VERSION "Toyota/Continental ARS510 radar bus (comma harness bus 1), frame-level. Object records need reassembly: see ars510/ and dbc/ars510_objects_vbus.dbc"

NS_ :

BS_:

BU_: RADAR CAMERA XXX

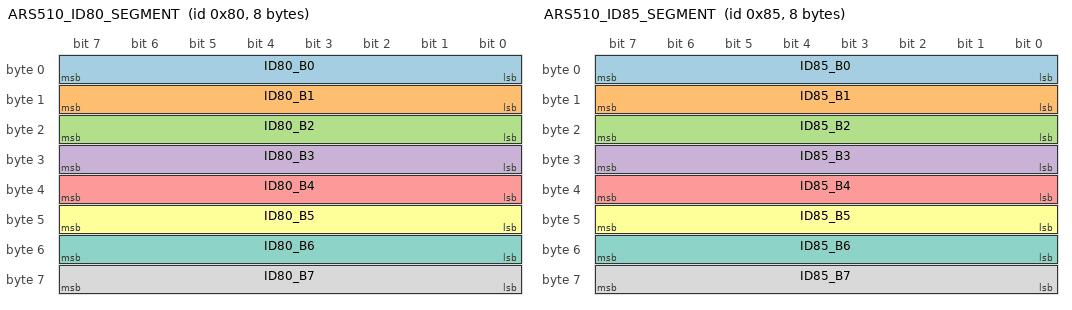
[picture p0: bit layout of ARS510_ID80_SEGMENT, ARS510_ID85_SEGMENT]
BO_ 128 ARS510_ID80_SEGMENT: 8 RADAR
 SG_ ID80_B0 : 0|8@1+ (1,0) [0|255] "raw" RADAR
 SG_ ID80_B1 : 8|8@1+ (1,0) [0|255] "raw" RADAR
 SG_ ID80_B2 : 16|8@1+ (1,0) [0|255] "raw" RADAR
 SG_ ID80_B3 : 24|8@1+ (1,0) [0|255] "raw" RADAR
 SG_ ID80_B4 : 32|8@1+ (1,0) [0|255] "raw" RADAR
 SG_ ID80_B5 : 40|8@1+ (1,0) [0|255] "raw" RADAR
 SG_ ID80_B6 : 48|8@1+ (1,0) [0|255] "raw" RADAR
 SG_ ID80_B7 : 56|8@1+ (1,0) [0|255] "raw" RADAR

BO_ 133 ARS510_ID85_SEGMENT: 8 RADAR
 SG_ ID85_B0 : 0|8@1+ (1,0) [0|255] "raw" RADAR
 SG_ ID85_B1 : 8|8@1+ (1,0) [0|255] "raw" RADAR
 SG_ ID85_B2 : 16|8@1+ (1,0) [0|255] "raw" RADAR
 SG_ ID85_B3 : 24|8@1+ (1,0) [0|255] "raw" RADAR
 SG_ ID85_B4 : 32|8@1+ (1,0) [0|255] "raw" RADAR
 SG_ ID85_B5 : 40|8@1+ (1,0) [0|255] "raw" RADAR
 SG_ ID85_B6 : 48|8@1+ (1,0) [0|255] "raw" RADAR
 SG_ ID85_B7 : 56|8@1+ (1,0) [0|255] "raw" RADAR

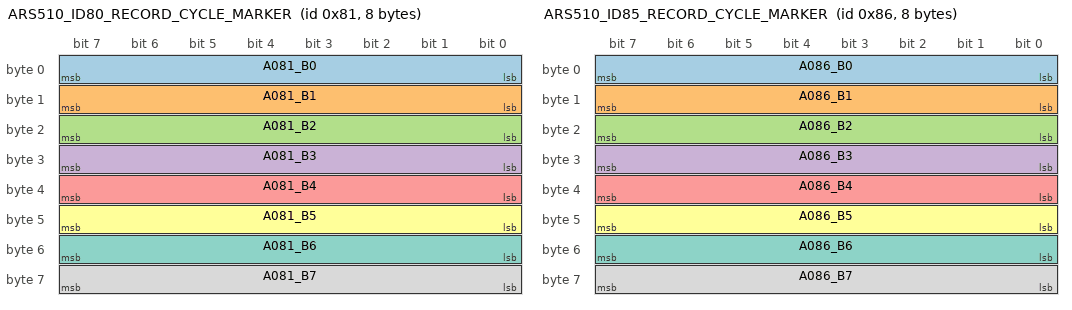
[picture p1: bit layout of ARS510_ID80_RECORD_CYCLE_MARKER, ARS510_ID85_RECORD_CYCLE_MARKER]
BO_ 129 ARS510_ID80_RECORD_CYCLE_MARKER: 8 RADAR
 SG_ A081_B0 : 0|8@1+ (1,0) [0|255] "raw" RADAR
 SG_ A081_B1 : 8|8@1+ (1,0) [0|255] "raw" RADAR
 SG_ A081_B2 : 16|8@1+ (1,0) [0|255] "raw" RADAR
 SG_ A081_B3 : 24|8@1+ (1,0) [0|255] "raw" RADAR
 SG_ A081_B4 : 32|8@1+ (1,0) [0|255] "raw" RADAR
 SG_ A081_B5 : 40|8@1+ (1,0) [0|255] "raw" RADAR
 SG_ A081_B6 : 48|8@1+ (1,0) [0|255] "raw" RADAR
 SG_ A081_B7 : 56|8@1+ (1,0) [0|255] "raw" RADAR

BO_ 134 ARS510_ID85_RECORD_CYCLE_MARKER: 8 RADAR
 SG_ A086_B0 : 0|8@1+ (1,0) [0|255] "raw" RADAR
 SG_ A086_B1 : 8|8@1+ (1,0) [0|255] "raw" RADAR
 SG_ A086_B2 : 16|8@1+ (1,0) [0|255] "raw" RADAR
 SG_ A086_B3 : 24|8@1+ (1,0) [0|255] "raw" RADAR
 SG_ A086_B4 : 32|8@1+ (1,0) [0|255] "raw" RADAR
 SG_ A086_B5 : 40|8@1+ (1,0) [0|255] "raw" RADAR
 SG_ A086_B6 : 48|8@1+ (1,0) [0|255] "raw" RADAR
 SG_ A086_B7 : 56|8@1+ (1,0) [0|255] "raw" RADAR

BO_ 256 ARS510_A100_CANDIDATE: 7 RADAR
 SG_ A100_STARTUP_WORD_BE16 : 7|16@0+ (1,0) [0|65535] "raw" RADAR
 SG_ A100_B2_B6_RESERVED_ZERO40 : 23|40@0+ (1,0) [0|1099511627775] "raw" RADAR

BO_ 257 ARS510_A101_CANDIDATE: 6 CAMERA
 SG_ A101_STARTUP_STATE8 : 0|8@1+ (1,0) [0|255] "state" RADAR
 SG_ A101_B1_B5_RESERVED_ZERO40 : 15|40@0+ (1,0) [0|1099511627775] "raw" RADAR

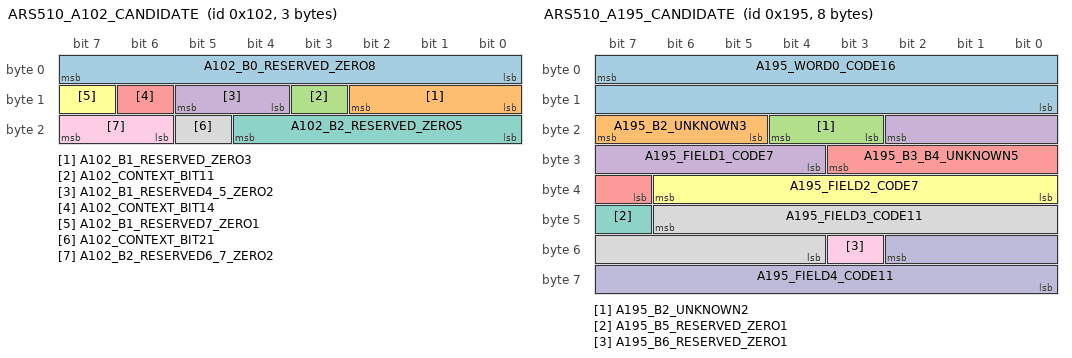
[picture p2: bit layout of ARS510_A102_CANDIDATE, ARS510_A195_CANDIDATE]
BO_ 258 ARS510_A102_CANDIDATE: 3 CAMERA
 SG_ A102_B0_RESERVED_ZERO8 : 0|8@1+ (1,0) [0|255] "raw" RADAR
 SG_ A102_B1_RESERVED_ZERO3 : 8|3@1+ (1,0) [0|7] "raw" RADAR
 SG_ A102_CONTEXT_BIT11 : 11|1@1+ (1,0) [0|1] "state" RADAR
 SG_ A102_B1_RESERVED4_5_ZERO2 : 12|2@1+ (1,0) [0|3] "raw" RADAR
 SG_ A102_CONTEXT_BIT14 : 14|1@1+ (1,0) [0|1] "state" RADAR
 SG_ A102_B1_RESERVED7_ZERO1 : 15|1@1+ (1,0) [0|1] "raw" RADAR
 SG_ A102_B2_RESERVED_ZERO5 : 16|5@1+ (1,0) [0|31] "raw" RADAR
 SG_ A102_CONTEXT_BIT21 : 21|1@1+ (1,0) [0|1] "state" RADAR
 SG_ A102_B2_RESERVED6_7_ZERO2 : 22|2@1+ (1,0) [0|3] "raw" RADAR

BO_ 259 ARS510_A103_CANDIDATE: 2 RADAR
 SG_ A103_B0_RESERVED_ZERO8 : 0|8@1+ (1,0) [0|255] "raw" RADAR
 SG_ A103_B1_RESERVED_ZERO8 : 8|8@1+ (1,0) [0|255] "raw" RADAR

BO_ 384 ARS510_A180_CANDIDATE: 5 CAMERA
 SG_ A180_OBSERVED_CONSTANT_BE40 : 7|40@0+ (1,0) [0|1099511627775] "raw" RADAR

BO_ 400 ARS510_A190_CANDIDATE: 7 RADAR
 SG_ A190_STATUS_0_4 : 0|4@1+ (1,0) [0|15] "state" RADAR
 SG_ A190_B0_HIGH4 : 4|4@1+ (1,0) [0|15] "raw" RADAR
 SG_ A190_ACTIVE_SUMMARIES : 3|2@0+ (1,0) [0|3] "count" RADAR
 SG_ A190_B1 : 8|8@1+ (1,0) [0|255] "raw" RADAR
 SG_ A190_TIMESTAMP_US : 23|32@0+ (1,0) [0|4294967295] "us" RADAR
 SG_ A190_COUNTER_RESERVED0 : 48|4@1+ (1,0) [0|15] "raw" RADAR
 SG_ A190_COUNTER4 : 52|4@1+ (1,0) [0|15] "counter" RADAR

BO_ 405 ARS510_A195_CANDIDATE: 8 RADAR
 SG_ A195_WORD0_CODE16 : 7|16@0+ (1,0) [0|65535] "code" RADAR
 SG_ A195_B2_UNKNOWN3 : 23|3@0+ (1,0) [0|7] "raw" RADAR
 SG_ A195_B2_UNKNOWN2 : 20|2@0+ (1,0) [0|3] "raw" RADAR
 SG_ A195_FIELD1_CODE7 : 18|7@0+ (1,0) [0|127] "code" RADAR
 SG_ A195_B3_B4_UNKNOWN5 : 27|5@0+ (1,0) [0|31] "raw" RADAR
 SG_ A195_FIELD2_CODE7 : 38|7@0+ (1,0) [0|127] "code" RADAR
 SG_ A195_B5_RESERVED_ZERO1 : 47|1@0+ (1,0) [0|1] "raw" RADAR
 SG_ A195_FIELD3_CODE11 : 46|11@0+ (1,0) [0|2047] "code" RADAR
 SG_ A195_B6_RESERVED_ZERO1 : 51|1@0+ (1,0) [0|1] "raw" RADAR
 SG_ A195_FIELD4_CODE11 : 50|11@0+ (1,0) [0|2047] "code" RADAR

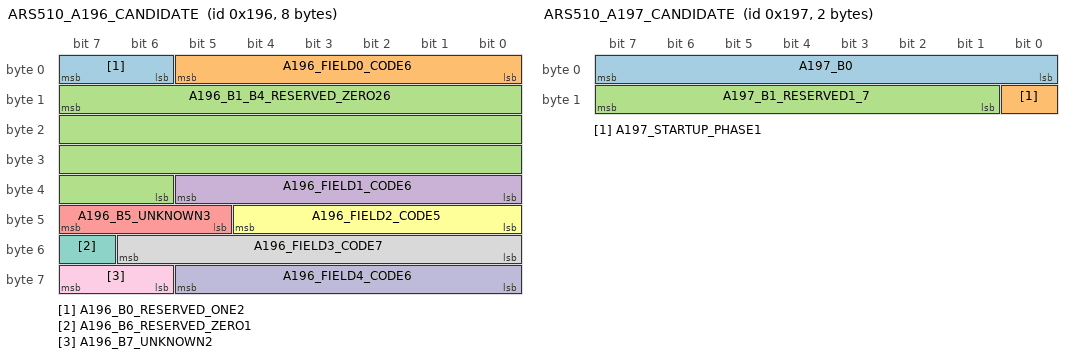
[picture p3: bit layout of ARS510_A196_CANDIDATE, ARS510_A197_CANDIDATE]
BO_ 406 ARS510_A196_CANDIDATE: 8 RADAR
 SG_ A196_B0_RESERVED_ONE2 : 7|2@0+ (1,0) [0|3] "raw" RADAR
 SG_ A196_FIELD0_CODE6 : 5|6@0+ (1,0) [0|63] "code" RADAR
 SG_ A196_B1_B4_RESERVED_ZERO26 : 15|26@0+ (1,0) [0|67108863] "raw" RADAR
 SG_ A196_FIELD1_CODE6 : 37|6@0+ (1,0) [0|63] "code" RADAR
 SG_ A196_B5_UNKNOWN3 : 47|3@0+ (1,0) [0|7] "raw" RADAR
 SG_ A196_FIELD2_CODE5 : 44|5@0+ (1,0) [0|31] "code" RADAR
 SG_ A196_B6_RESERVED_ZERO1 : 55|1@0+ (1,0) [0|1] "raw" RADAR
 SG_ A196_FIELD3_CODE7 : 54|7@0+ (1,0) [0|127] "code" RADAR
 SG_ A196_B7_UNKNOWN2 : 63|2@0+ (1,0) [0|3] "raw" RADAR
 SG_ A196_FIELD4_CODE6 : 61|6@0+ (1,0) [0|63] "code" RADAR

BO_ 407 ARS510_A197_CANDIDATE: 2 CAMERA
 SG_ A197_B0 : 0|8@1+ (1,0) [0|255] "raw" RADAR
 SG_ A197_STARTUP_PHASE1 : 8|1@1+ (1,0) [0|1] "state" RADAR
 SG_ A197_B1_RESERVED1_7 : 9|7@1+ (1,0) [0|127] "raw" RADAR

BO_ 408 ARS510_A198_CANDIDATE: 1 RADAR
 SG_ A198_OBSERVED_CONSTANT_BE8 : 7|8@0+ (1,0) [0|255] "raw" RADAR

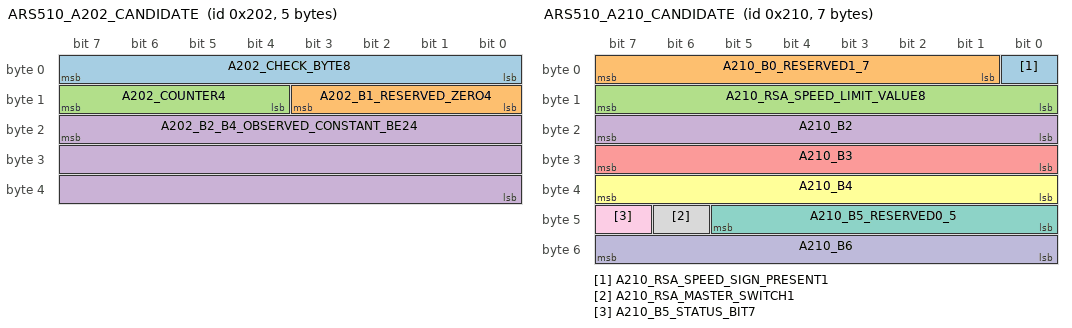
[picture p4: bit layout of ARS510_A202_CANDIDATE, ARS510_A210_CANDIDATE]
BO_ 514 ARS510_A202_CANDIDATE: 5 RADAR
 SG_ A202_CHECK_BYTE8 : 0|8@1+ (1,0) [0|255] "debug" RADAR
 SG_ A202_B1_RESERVED_ZERO4 : 8|4@1+ (1,0) [0|15] "raw" RADAR
 SG_ A202_COUNTER4 : 12|4@1+ (1,0) [0|15] "counter" RADAR
 SG_ A202_B2_B4_OBSERVED_CONSTANT_BE24 : 23|24@0+ (1,0) [0|16777215] "raw" RADAR

BO_ 528 ARS510_A210_CANDIDATE: 7 CAMERA
 SG_ A210_RSA_SPEED_SIGN_PRESENT1 : 0|1@1+ (1,0) [0|1] "state" RADAR
 SG_ A210_B0_RESERVED1_7 : 1|7@1+ (1,0) [0|127] "raw" RADAR
 SG_ A210_RSA_SPEED_LIMIT_VALUE8 : 8|8@1+ (1,0) [0|255] "display_speed" RADAR
 SG_ A210_B2 : 16|8@1+ (1,0) [0|255] "raw" RADAR
 SG_ A210_B3 : 24|8@1+ (1,0) [0|255] "raw" RADAR
 SG_ A210_B4 : 32|8@1+ (1,0) [0|255] "raw" RADAR
 SG_ A210_B5_RESERVED0_5 : 40|6@1+ (1,0) [0|63] "raw" RADAR
 SG_ A210_RSA_MASTER_SWITCH1 : 46|1@1+ (1,0) [0|1] "state" RADAR
 SG_ A210_B5_STATUS_BIT7 : 47|1@1+ (1,0) [0|1] "state" RADAR
 SG_ A210_B6 : 48|8@1+ (1,0) [0|255] "raw" RADAR

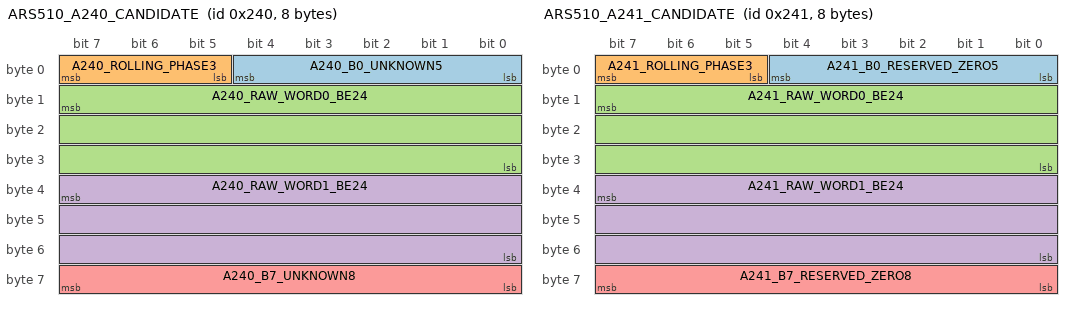
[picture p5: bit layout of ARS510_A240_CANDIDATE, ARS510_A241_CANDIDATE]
BO_ 576 ARS510_A240_CANDIDATE: 8 CAMERA
 SG_ A240_B0_UNKNOWN5 : 0|5@1+ (1,0) [0|31] "raw" RADAR
 SG_ A240_ROLLING_PHASE3 : 5|3@1+ (1,0) [0|7] "state" RADAR
 SG_ A240_RAW_WORD0_BE24 : 15|24@0+ (1,0) [0|16777215] "raw" RADAR
 SG_ A240_RAW_WORD1_BE24 : 39|24@0+ (1,0) [0|16777215] "raw" RADAR
 SG_ A240_B7_UNKNOWN8 : 56|8@1+ (1,0) [0|255] "raw" RADAR

BO_ 577 ARS510_A241_CANDIDATE: 8 CAMERA
 SG_ A241_B0_RESERVED_ZERO5 : 0|5@1+ (1,0) [0|31] "raw" RADAR
 SG_ A241_ROLLING_PHASE3 : 5|3@1+ (1,0) [0|7] "state" RADAR
 SG_ A241_RAW_WORD0_BE24 : 15|24@0+ (1,0) [0|16777215] "raw" RADAR
 SG_ A241_RAW_WORD1_BE24 : 39|24@0+ (1,0) [0|16777215] "raw" RADAR
 SG_ A241_B7_RESERVED_ZERO8 : 56|8@1+ (1,0) [0|255] "raw" RADAR

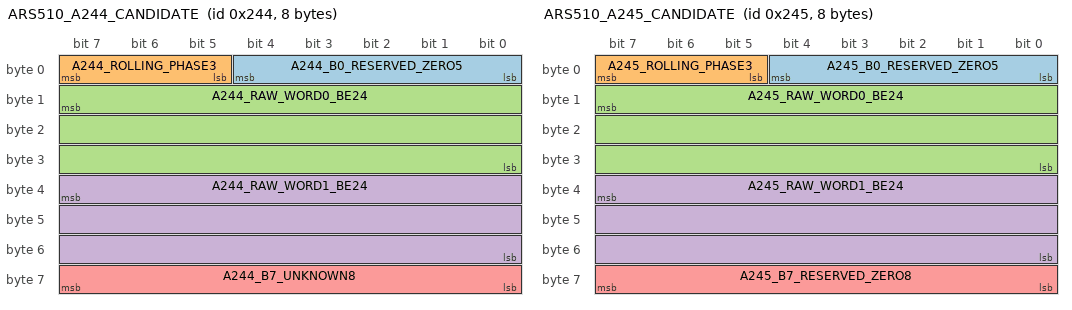
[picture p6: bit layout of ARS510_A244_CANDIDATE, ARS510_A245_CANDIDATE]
BO_ 580 ARS510_A244_CANDIDATE: 8 CAMERA
 SG_ A244_B0_RESERVED_ZERO5 : 0|5@1+ (1,0) [0|31] "raw" RADAR
 SG_ A244_ROLLING_PHASE3 : 5|3@1+ (1,0) [0|7] "state" RADAR
 SG_ A244_RAW_WORD0_BE24 : 15|24@0+ (1,0) [0|16777215] "raw" RADAR
 SG_ A244_RAW_WORD1_BE24 : 39|24@0+ (1,0) [0|16777215] "raw" RADAR
 SG_ A244_B7_UNKNOWN8 : 56|8@1+ (1,0) [0|255] "raw" RADAR

BO_ 581 ARS510_A245_CANDIDATE: 8 CAMERA
 SG_ A245_B0_RESERVED_ZERO5 : 0|5@1+ (1,0) [0|31] "raw" RADAR
 SG_ A245_ROLLING_PHASE3 : 5|3@1+ (1,0) [0|7] "state" RADAR
 SG_ A245_RAW_WORD0_BE24 : 15|24@0+ (1,0) [0|16777215] "raw" RADAR
 SG_ A245_RAW_WORD1_BE24 : 39|24@0+ (1,0) [0|16777215] "raw" RADAR
 SG_ A245_B7_RESERVED_ZERO8 : 56|8@1+ (1,0) [0|255] "raw" RADAR

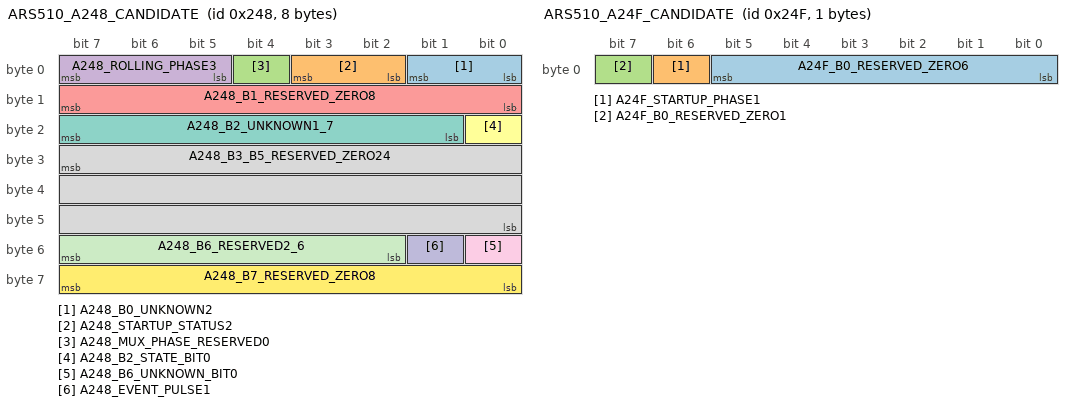
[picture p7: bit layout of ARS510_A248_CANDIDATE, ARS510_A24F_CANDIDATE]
BO_ 584 ARS510_A248_CANDIDATE: 8 CAMERA
 SG_ A248_B0_UNKNOWN2 : 0|2@1+ (1,0) [0|3] "raw" RADAR
 SG_ A248_STARTUP_STATUS2 : 2|2@1+ (1,0) [0|3] "state" RADAR
 SG_ A248_MUX_PHASE_RESERVED0 : 4|1@1+ (1,0) [0|1] "raw" RADAR
 SG_ A248_ROLLING_PHASE3 : 5|3@1+ (1,0) [0|7] "state" RADAR
 SG_ A248_B1_RESERVED_ZERO8 : 8|8@1+ (1,0) [0|255] "raw" RADAR
 SG_ A248_B2_STATE_BIT0 : 16|1@1+ (1,0) [0|1] "state" RADAR
 SG_ A248_B2_UNKNOWN1_7 : 17|7@1+ (1,0) [0|127] "raw" RADAR
 SG_ A248_B3_B5_RESERVED_ZERO24 : 31|24@0+ (1,0) [0|16777215] "raw" RADAR
 SG_ A248_B6_UNKNOWN_BIT0 : 48|1@1+ (1,0) [0|1] "raw" RADAR
 SG_ A248_EVENT_PULSE1 : 49|1@1+ (1,0) [0|1] "state" RADAR
 SG_ A248_B6_RESERVED2_6 : 50|6@1+ (1,0) [0|63] "raw" RADAR
 SG_ A248_B7_RESERVED_ZERO8 : 56|8@1+ (1,0) [0|255] "raw" RADAR

BO_ 589 ARS510_A24D_CANDIDATE: 7 CAMERA
 SG_ A24D_OBSERVED_CONSTANT_BE56 : 7|56@0+ (1,0) [0|72057594037927935] "raw" RADAR

BO_ 591 ARS510_A24F_CANDIDATE: 1 RADAR
 SG_ A24F_B0_RESERVED_ZERO6 : 0|6@1+ (1,0) [0|63] "raw" RADAR
 SG_ A24F_STARTUP_PHASE1 : 6|1@1+ (1,0) [0|1] "state" RADAR
 SG_ A24F_B0_RESERVED_ZERO1 : 7|1@1+ (1,0) [0|1] "raw" RADAR

BO_ 1280 ARS510_A500_CANDIDATE: 6 CAMERA
 SG_ A500_OBSERVED_CONSTANT_BE48 : 7|48@0+ (1,0) [0|281474976710655] "raw" RADAR

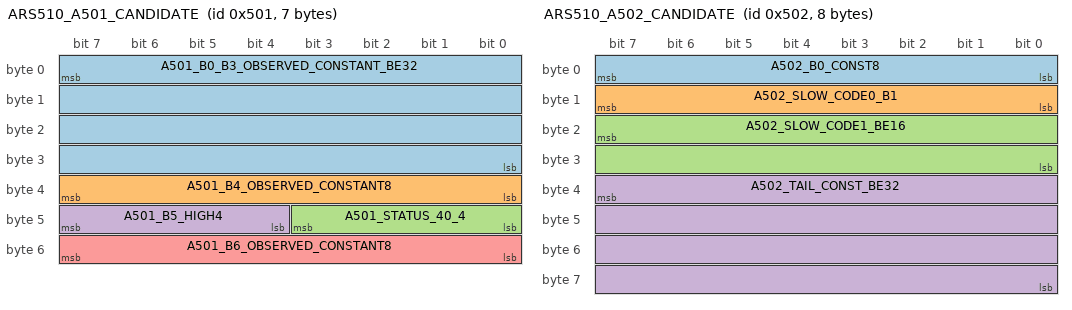
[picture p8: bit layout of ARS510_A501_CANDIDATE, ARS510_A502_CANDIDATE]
BO_ 1281 ARS510_A501_CANDIDATE: 7 CAMERA
 SG_ A501_B0_B3_OBSERVED_CONSTANT_BE32 : 7|32@0+ (1,0) [0|4294967295] "raw" RADAR
 SG_ A501_B4_OBSERVED_CONSTANT8 : 32|8@1+ (1,0) [0|255] "raw" RADAR
 SG_ A501_STATUS_40_4 : 40|4@1+ (1,0) [0|15] "state" RADAR
 SG_ A501_B5_HIGH4 : 44|4@1+ (1,0) [0|15] "raw" RADAR
 SG_ A501_B6_OBSERVED_CONSTANT8 : 48|8@1+ (1,0) [0|255] "raw" RADAR

BO_ 1282 ARS510_A502_CANDIDATE: 8 RADAR
 SG_ A502_B0_CONST8 : 0|8@1+ (1,0) [0|255] "raw" RADAR
 SG_ A502_SLOW_CODE0_B1 : 8|8@1+ (1,0) [0|255] "raw" RADAR
 SG_ A502_SLOW_CODE1_BE16 : 23|16@0+ (1,0) [0|65535] "raw" RADAR
 SG_ A502_TAIL_CONST_BE32 : 39|32@0+ (1,0) [0|4294967295] "raw" RADAR

BO_ 1664 ARS510_A680_OBJECT: 8 RADAR
 SG_ A680_SELECTOR : 7|8@0+ (1,0) [0|255] "code" RADAR
 SG_ A680_LONG_DIST : 15|13@0+ (0.03125,0) [0|255.97] "m" RADAR
 SG_ A680_LAT_DIST : 18|11@0- (0.015,0) [-15.36|15.345] "m" RADAR
 SG_ A680_SPEED_OVER_GROUND : 39|10@0+ (0.15,-76.8) [-76.8|76.65] "m/s" RADAR
 SG_ A680_FLAGS : 45|6@0+ (1,0) [0|63] "raw" RADAR
 SG_ A680_STATIONARY : 40|1@0+ (1,0) [0|1] "" RADAR
 SG_ A680_ONCOMING : 41|1@0+ (1,0) [0|1] "" RADAR
 SG_ A680_SEEN_MOVING : 43|1@0+ (1,0) [0|1] "" RADAR
 SG_ A680_LAT_SPEED_CODE : 55|8@0+ (1,-128) [-128|127] "code" RADAR
 SG_ A680_B7_HIGH4 : 63|4@0+ (1,0) [0|15] "raw" RADAR
 SG_ A680_B7_LOW4 : 59|4@0+ (1,0) [0|15] "raw" RADAR

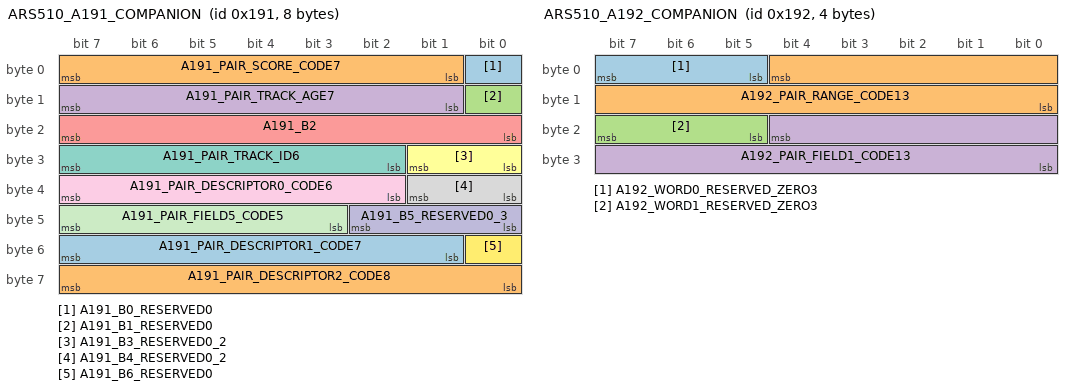
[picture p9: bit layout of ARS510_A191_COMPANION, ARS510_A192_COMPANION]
BO_ 401 ARS510_A191_COMPANION: 8 RADAR
 SG_ A191_B0_RESERVED0 : 0|1@1+ (1,0) [0|1] "raw" RADAR
 SG_ A191_PAIR_SCORE_CODE7 : 1|7@1+ (1,0) [0|127] "code" RADAR
 SG_ A191_B1_RESERVED0 : 8|1@1+ (1,0) [0|1] "raw" RADAR
 SG_ A191_PAIR_TRACK_AGE7 : 9|7@1+ (1,0) [0|127] "radar_cycle" RADAR
 SG_ A191_B2 : 16|8@1+ (1,0) [0|255] "raw" RADAR
 SG_ A191_B3_RESERVED0_2 : 24|2@1+ (1,0) [0|3] "raw" RADAR
 SG_ A191_PAIR_TRACK_ID6 : 26|6@1+ (1,0) [0|63] "code" RADAR
 SG_ A191_B4_RESERVED0_2 : 32|2@1+ (1,0) [0|3] "raw" RADAR
 SG_ A191_PAIR_DESCRIPTOR0_CODE6 : 34|6@1+ (0.1,0) [0|6.3] "m" RADAR
 SG_ A191_B5_RESERVED0_3 : 40|3@1+ (1,0) [0|7] "raw" RADAR
 SG_ A191_PAIR_FIELD5_CODE5 : 43|5@1+ (1,0) [0|31] "code" RADAR
 SG_ A191_B6_RESERVED0 : 48|1@1+ (1,0) [0|1] "raw" RADAR
 SG_ A191_PAIR_DESCRIPTOR1_CODE7 : 49|7@1+ (0.1,0) [0|12.7] "m" RADAR
 SG_ A191_PAIR_DESCRIPTOR2_CODE8 : 56|8@1+ (0.1,0) [0|25.5] "m" RADAR

BO_ 402 ARS510_A192_COMPANION: 4 RADAR
 SG_ A192_WORD0_RESERVED_ZERO3 : 5|3@1+ (1,0) [0|7] "raw" RADAR
 SG_ A192_PAIR_RANGE_CODE13 : 4|13@0+ (0.0625,-10) [-10|501.94] "m" RADAR
 SG_ A192_WORD1_RESERVED_ZERO3 : 21|3@1+ (1,0) [0|7] "raw" RADAR
 SG_ A192_PAIR_FIELD1_CODE13 : 20|13@0+ (0.015,-30.72) [-30.72|92.145] "m" RADAR

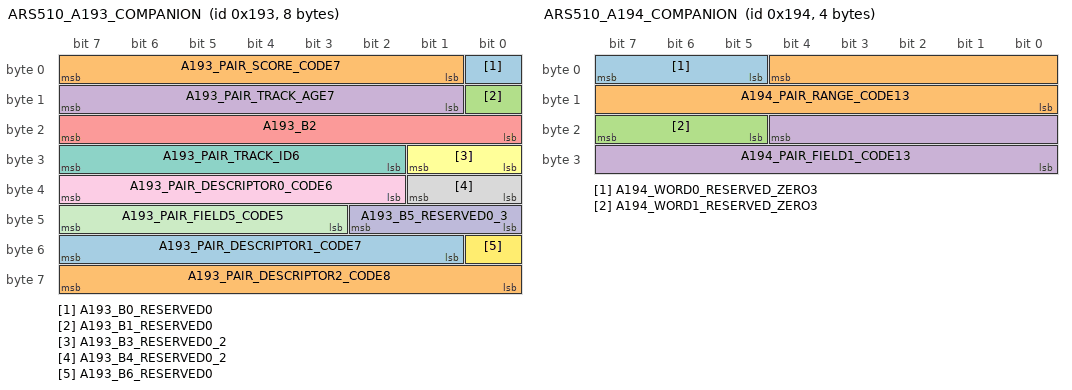
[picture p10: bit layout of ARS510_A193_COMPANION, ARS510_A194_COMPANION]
BO_ 403 ARS510_A193_COMPANION: 8 RADAR
 SG_ A193_B0_RESERVED0 : 0|1@1+ (1,0) [0|1] "raw" RADAR
 SG_ A193_PAIR_SCORE_CODE7 : 1|7@1+ (1,0) [0|127] "code" RADAR
 SG_ A193_B1_RESERVED0 : 8|1@1+ (1,0) [0|1] "raw" RADAR
 SG_ A193_PAIR_TRACK_AGE7 : 9|7@1+ (1,0) [0|127] "radar_cycle" RADAR
 SG_ A193_B2 : 16|8@1+ (1,0) [0|255] "raw" RADAR
 SG_ A193_B3_RESERVED0_2 : 24|2@1+ (1,0) [0|3] "raw" RADAR
 SG_ A193_PAIR_TRACK_ID6 : 26|6@1+ (1,0) [0|63] "code" RADAR
 SG_ A193_B4_RESERVED0_2 : 32|2@1+ (1,0) [0|3] "raw" RADAR
 SG_ A193_PAIR_DESCRIPTOR0_CODE6 : 34|6@1+ (0.1,0) [0|6.3] "m" RADAR
 SG_ A193_B5_RESERVED0_3 : 40|3@1+ (1,0) [0|7] "raw" RADAR
 SG_ A193_PAIR_FIELD5_CODE5 : 43|5@1+ (1,0) [0|31] "code" RADAR
 SG_ A193_B6_RESERVED0 : 48|1@1+ (1,0) [0|1] "raw" RADAR
 SG_ A193_PAIR_DESCRIPTOR1_CODE7 : 49|7@1+ (0.1,0) [0|12.7] "m" RADAR
 SG_ A193_PAIR_DESCRIPTOR2_CODE8 : 56|8@1+ (0.1,0) [0|25.5] "m" RADAR

BO_ 404 ARS510_A194_COMPANION: 4 RADAR
 SG_ A194_WORD0_RESERVED_ZERO3 : 5|3@1+ (1,0) [0|7] "raw" RADAR
 SG_ A194_PAIR_RANGE_CODE13 : 4|13@0+ (0.0625,-10) [-10|501.94] "m" RADAR
 SG_ A194_WORD1_RESERVED_ZERO3 : 21|3@1+ (1,0) [0|7] "raw" RADAR
 SG_ A194_PAIR_FIELD1_CODE13 : 20|13@0+ (0.015,-30.72) [-30.72|92.145] "m" RADAR

BO_ 565 ARS510_A235_COMPANION: 8 RADAR
 SG_ A235_B0_CHECK_BYTE : 0|8@1+ (1,0) [0|255] "debug" RADAR
 SG_ A235_STATUS_MUX4 : 8|4@1+ (1,0) [0|15] "state" RADAR
 SG_ A235_COUNTER4 : 12|4@1+ (1,0) [0|15] "counter" RADAR
 SG_ A235_B2 : 16|8@1+ (1,0) [0|255] "raw" RADAR
 SG_ A235_B3 : 24|8@1+ (1,0) [0|255] "raw" RADAR
 SG_ A235_B4 : 32|8@1+ (1,0) [0|255] "raw" RADAR
 SG_ A235_B5 : 40|8@1+ (1,0) [0|255] "raw" RADAR
 SG_ A235_B6 : 48|8@1+ (1,0) [0|255] "raw" RADAR
 SG_ A235_B7 : 56|8@1+ (1,0) [0|255] "raw" RADAR
 SG_ A235_ACC_TARGET_VREL : 31|11@0+ (0.125,-128) [-128|127.875] "m/s" RADAR
 SG_ A235_ACC_TARGET_AREL : 16|8@1+ (0.125,-12.5) [-12.5|19.375] "m/s^2" RADAR
 SG_ A235_ACC_TARGET_VLAT : 42|11@0+ (0.0125,-12.8) [-12.8|12.7875] "m/s" RADAR
 SG_ A235_ACC_TARGET_ALAT : 34|8@0+ (0.125,-12.5) [-12.5|19.375] "m/s^2" RADAR
 SG_ A235_TARGET_ID5 : 60|5@0+ (1,0) [0|31] "id" RADAR

BO_ 567 ARS510_A237_COMPANION: 8 RADAR
 SG_ A237_B0_CHECK_BYTE : 0|8@1+ (1,0) [0|255] "debug" RADAR
 SG_ A237_STATUS_MUX4 : 8|4@1+ (1,0) [0|15] "state" RADAR
 SG_ A237_COUNTER4 : 12|4@1+ (1,0) [0|15] "counter" RADAR
 SG_ A237_B2 : 16|8@1+ (1,0) [0|255] "raw" RADAR
 SG_ A237_B3 : 24|8@1+ (1,0) [0|255] "raw" RADAR
 SG_ A237_B4 : 32|8@1+ (1,0) [0|255] "raw" RADAR
 SG_ A237_B5 : 40|8@1+ (1,0) [0|255] "raw" RADAR
 SG_ A237_B6 : 48|8@1+ (1,0) [0|255] "raw" RADAR
 SG_ A237_B7 : 56|8@1+ (1,0) [0|255] "raw" RADAR
 SG_ A237_ACC_TARGET_LAT : 30|12@0+ (0.01,-20) [-20|20.95] "m" RADAR
 SG_ A237_TRACKER_A8 : 34|8@0+ (1,0) [0|255] "code" RADAR
 SG_ A237_TRACKER_B8 : 42|8@0+ (1,0) [0|255] "code" RADAR
 SG_ A237_TARGET_PRESENT : 50|1@0+ (1,0) [0|1] "flag" RADAR
 SG_ A237_IN_PATH_CONFIRMED : 48|1@0+ (1,0) [0|1] "flag" RADAR
 SG_ A237_IN_PATH_CANDIDATE : 63|1@0+ (1,0) [0|1] "flag" RADAR
 SG_ A237_IN_PATH_LEVEL3 : 62|3@0+ (1,0) [0|7] "level" RADAR
 SG_ A237_ACC_TARGET_DISTANCE_CODE : 11|13@0+ (0.025,0) [0|204.775] "m" RADAR

BO_ 569 ARS510_A239_COMPANION: 8 RADAR
 SG_ A239_B0_CHECK_BYTE : 0|8@1+ (1,0) [0|255] "debug" RADAR
 SG_ A239_STATUS_MUX4 : 8|4@1+ (1,0) [0|15] "state" RADAR
 SG_ A239_COUNTER4 : 12|4@1+ (1,0) [0|15] "counter" RADAR
 SG_ A239_B2 : 16|8@1+ (1,0) [0|255] "raw" RADAR
 SG_ A239_B3 : 24|8@1+ (1,0) [0|255] "raw" RADAR
 SG_ A239_B4 : 32|8@1+ (1,0) [0|255] "raw" RADAR
 SG_ A239_B5 : 40|8@1+ (1,0) [0|255] "raw" RADAR
 SG_ A239_B6 : 48|8@1+ (1,0) [0|255] "raw" RADAR
 SG_ A239_B7 : 56|8@1+ (1,0) [0|255] "raw" RADAR
 SG_ A239_TARGET_IN_OBJECT_LIST : 31|1@0+ (1,0) [0|1] "flag" RADAR
 SG_ A239_TARGET_PRESENT : 27|1@0+ (1,0) [0|1] "flag" RADAR
 SG_ A239_TIMESTAMP_US : 26|32@0+ (1,0) [0|4294967295] "us" RADAR

BO_ 571 ARS510_A23B_COMPANION: 3 RADAR
 SG_ A23B_B0_CHECK_BYTE : 0|8@1+ (1,0) [0|255] "debug" RADAR
 SG_ A23B_STATUS_MUX4 : 8|4@1+ (1,0) [0|15] "state" RADAR
 SG_ A23B_COUNTER4 : 12|4@1+ (1,0) [0|15] "counter" RADAR
 SG_ A23B_B2 : 16|8@1+ (1,0) [0|255] "raw" RADAR
 SG_ A23B_TARGET_WIDTH_CM : 11|12@0+ (1,0) [0|4095] "cm" RADAR

BO_ 573 ARS510_A23D_COMPANION: 8 RADAR
 SG_ A23D_OBSERVED_CONSTANT_BE64 : 7|64@0+ (1,0) [0|18446744073709551615] "raw" RADAR

CM_ "ARS510 radar bus (comma harness bus 1), frame-local view. The 0x80 object list and 0x85 metadata record are segmented over many frames and are reassembled in code (ars510.transport); their frames appear here only as raw bytes. Decoded objects are in ars510_objects_vbus.dbc. Documentation: github.com/ds-sebastian/ars510-radar docs/.";
CM_ BO_ 128 "0x80 object-list transport: a 742-byte record (20 object slots + CRC32) sent every 60 ms as 106 ISO-TP-like frames. First frame starts 12 E4; bytes 1-7 of each frame are appended.";
CM_ BO_ 133 "0x85 metadata-record transport: a 147-byte record (prefix, ten 12-byte cells, CRC32) sent every 60 ms as 21 frames. First frame starts 10 90.";
CM_ BO_ 129 "Record-cycle marker: 30 00 00 00 00 00 00 00 within 20 ms after each 0x80 record start.";
CM_ BO_ 134 "Record-cycle marker: 30 00 00 00 00 00 00 00 within 20 ms after each 0x85 record start.";
CM_ BO_ 256 "Startup context: word 0 is 0xFFFF in the first frame after power-up, zero afterwards.";
CM_ BO_ 257 "Camera-sent radar-running state: 0x1D while the radar boots, 0x11 once its object list arrives (switches 60 ms before 0x197 bit 8 sets).";
CM_ BO_ 258 "Sparse state bits 11, 14 and 21.";
CM_ BO_ 259 "Always zero.";
CM_ BO_ 384 "Constant CF C0 00 00 00.";
CM_ BO_ 400 "Radar cycle header (16.7 Hz): number of target summaries, microsecond timestamp and a mod-16 cycle counter.";
CM_ BO_ 401 "Selected-target companion A (with 0x192): score, age and track code of a target the radar selects itself. Sentinel FE FE FE FC FC FF FE FF = no target.";
CM_ BO_ 402 "Selected-target summary A (4 bytes): distance and lateral position of one target of the radar's internal tracker, in the object list's encoding. Sentinel 00 FF 00 FF = no target.";
CM_ BO_ 403 "Selected-target companion B (with 0x194); same layout as 0x191.";
CM_ BO_ 404 "Selected-target summary B; same layout as 0x192.";
CM_ BO_ 405 "Event frame, paired with 0x196: exact idle payload on 99.67% of frames; non-idle in a short-time-to-collision state (docs/05).";
CM_ BO_ 406 "Event frame, paired with 0x195.";
CM_ BO_ 407 "Startup phase: bit 8 sets once the radar is running and stays set.";
CM_ BO_ 408 "Constant 0x10.";
CM_ BO_ 514 "Counter frame: byte 1 high nibble counts mod 16; byte 0 is a check byte that depends only on the counter.";
CM_ BO_ 528 "Copy of Toyota road-sign-assist data (speed-sign presence, speed-limit value, TSR switch).";
CM_ BO_ 565 "The radar's ACC target, 50 Hz (content per 60 ms radar cycle): closing speed, relative acceleration, lateral speed and acceleration and the target ID. Position and in-path state are on 0x237.";
CM_ SG_ 565 A235_ACC_TARGET_VREL "Closing speed of the ACC target, m/s, negative = closing; 0.125 m/s per code (stopped leads, distance slope).";
CM_ SG_ 565 A235_ACC_TARGET_AREL "Relative acceleration of the ACC target (positive = opening): (code - 100) * 0.125 m/s^2; one code is one speed code per second (closure 1.00 over 2 s windows). Code 100 is the idle value.";
CM_ SG_ 565 A235_ACC_TARGET_VLAT "Lateral speed of the ACC target, left positive, about 0.0125 m/s per code (the lateral position changes by 1.2 cm per code-second).";
CM_ SG_ 565 A235_ACC_TARGET_ALAT "Relative lateral acceleration of the ACC target, left positive: (code - 100) * 0.125 m/s^2 (nominal unit, as the longitudinal field). Mostly minus the ego lateral acceleration (-8.2 codes per m/s^2), plus a lateral-speed term; lags the yaw rate.";
CM_ SG_ 565 A235_TARGET_ID5 "Target identity: constant while the radar follows one target; 31 with the idle payload.";
CM_ SG_ 565 A235_B7 "Byte 7: bits 0-4 the target identity (A235_TARGET_ID5); bits 5-7 = 0 with an ACC target, 7 idle.";
CM_ SG_ 569 A239_B2 "Byte 2: bits 6-7 = 1 with an ACC target, 2 idle.";
CM_ BO_ 567 "The radar's ACC target, 50 Hz: distance, lateral position, in-path state and two tracker bytes (see 0x235).";
CM_ SG_ 567 A237_ACC_TARGET_LAT "Lateral position of the ACC target, m, left positive: 12 bits, (code - 2000) * 0.01. One object-list lateral code is 1.5 of these codes (1.499-1.502 on five sets).";
CM_ SG_ 567 A237_TRACKER_A8 "Raw tracker byte: 35-36 on a steady target, 44-50 while it accelerates, a median of 48-74 while it brakes.";
CM_ SG_ 567 A237_TRACKER_B8 "Raw tracker byte: about 86 for a stopped target, 128-135 for a steady mover, rises toward 240 (and wraps) while the target accelerates or brakes.";
CM_ SG_ 567 A237_TARGET_PRESENT "1 with an ACC target.";
CM_ SG_ 567 A237_IN_PATH_CONFIRMED "1 while the target is confirmed in the path (level 5).";
CM_ SG_ 567 A237_IN_PATH_CANDIDATE "1 while the target is a candidate (levels 4-2).";
CM_ SG_ 567 A237_IN_PATH_LEVEL3 "In-path level 5, 4, 3, 2; steps to the neighbouring level only; lower levels sit farther from the path.";
CM_ SG_ 567 A237_ACC_TARGET_DISTANCE_CODE "Distance of the ACC target, 0.025 m per code, zero offset (0.02 m median residual against the 0x680 object range).";
CM_ BO_ 569 "50 Hz companion of the ACC target: target class, object-list flag and the radar cycle timestamp of the 0x235 / 0x237 content.";
CM_ BO_ 571 "50 Hz companion of the ACC target (3 bytes): CRC-8, counter and the target width in cm.";
CM_ BO_ 573 "Always zero.";
CM_ BO_ 576 "Context frame, 16.7 Hz, rolling phase 1-7 in byte 0. At night carries light-source records (two per frame, paired with 0x244); default body by day.";
CM_ BO_ 577 "Context frame, 16.7 Hz, rolling phase 1-7 in byte 0; default body.";
CM_ BO_ 580 "Context frame, 16.7 Hz, rolling phase 1-7 in byte 0. At night carries light-source records (two per frame, paired with 0x240); bytes 4 and 7 are always equal.";
CM_ BO_ 581 "Context frame, 16.7 Hz, rolling phase 1-7 in byte 0; default body.";
CM_ BO_ 584 "Startup / event context frame with the same rolling phase as 0x240-0x245.";
CM_ BO_ 589 "State frame: 00 00 00 00 00 00 56 normally; 00 00 00 00 02 00 58 in a rare second state.";
CM_ BO_ 591 "Startup phase: bit 6 sets once the radar is running.";
CM_ BO_ 1280 "Constant, unit-specific payload (redacted here; compare your own).";
CM_ BO_ 1281 "Slow status frame: constants plus a 4-bit state at bit 40.";
CM_ BO_ 1282 "Slow state frame (every 3 s): two slowly drifting codes (bytes 1 and 2-3) and a unit-specific constant tail (redacted).";
CM_ BO_ 1664 "One object from the radar's function-level tracker (2 Hz): mostly a stationary roadside object, sometimes a vehicle. Idle payload 00 00 08 00 80 00 80 0A.";
CM_ SG_ 514 A202_CHECK_BYTE8 "Check byte, a fixed function of A202_COUNTER4: 0:10 1:8D 2:37 3:AA 4:5E 5:C3 6:79 7:E4 8:8C 9:11 10:AB 11:36 12:C2 13:5F 14:E5 15:78 (hex).";
CM_ SG_ 514 A202_B1_RESERVED_ZERO4 "Always zero.";
CM_ SG_ 514 A202_B2_B4_OBSERVED_CONSTANT_BE24 "Constant 0x036D80.";
CM_ SG_ 591 A24F_B0_RESERVED_ZERO6 "Always zero.";
CM_ SG_ 591 A24F_STARTUP_PHASE1 "0 while the radar starts up, 1 once running (stays 1).";
CM_ SG_ 591 A24F_B0_RESERVED_ZERO1 "Always zero.";
CM_ SG_ 1281 A501_B0_B3_OBSERVED_CONSTANT_BE32 "Constant 0xFFF0FFF0.";
CM_ SG_ 1281 A501_B4_OBSERVED_CONSTANT8 "Constant 0x70.";
CM_ SG_ 1281 A501_B6_OBSERVED_CONSTANT8 "Constant 0x00.";
CM_ SG_ 384 A180_OBSERVED_CONSTANT_BE40 "Constant 0xCFC0000000.";
CM_ SG_ 408 A198_OBSERVED_CONSTANT_BE8 "Constant 0x10.";
CM_ SG_ 573 A23D_OBSERVED_CONSTANT_BE64 "Always zero.";
CM_ SG_ 589 A24D_OBSERVED_CONSTANT_BE56 "00000000000056 normally; 00000000020058 in a rare second state.";
CM_ SG_ 1280 A500_OBSERVED_CONSTANT_BE48 "Unit-specific constant (redacted here; compare your own).";
CM_ SG_ 405 A195_WORD0_CODE16 "Event word, 32766 when idle.";
CM_ SG_ 405 A195_B2_UNKNOWN3 "Raw.";
CM_ SG_ 405 A195_B2_UNKNOWN2 "Raw.";
CM_ SG_ 405 A195_FIELD1_CODE7 "Event code, 126 when idle. Bits 18-27 (MSB-first) together form one 10-bit code: ((B2 & 0x3F) << 4) | (B3 >> 4), 510 when idle.";
CM_ SG_ 405 A195_B3_B4_UNKNOWN5 "Raw.";
CM_ SG_ 405 A195_FIELD2_CODE7 "Raw.";
CM_ SG_ 405 A195_B5_RESERVED_ZERO1 "Always zero.";
CM_ SG_ 405 A195_FIELD3_CODE11 "Raw.";
CM_ SG_ 405 A195_B6_RESERVED_ZERO1 "Always zero.";
CM_ SG_ 405 A195_FIELD4_CODE11 "Raw.";
CM_ SG_ 406 A196_B0_RESERVED_ONE2 "Always 3.";
CM_ SG_ 406 A196_FIELD0_CODE6 "Raw.";
CM_ SG_ 406 A196_B1_B4_RESERVED_ZERO26 "Always zero.";
CM_ SG_ 406 A196_FIELD1_CODE6 "Raw.";
CM_ SG_ 406 A196_B5_UNKNOWN3 "Raw.";
CM_ SG_ 406 A196_FIELD2_CODE5 "Raw.";
CM_ SG_ 406 A196_B6_RESERVED_ZERO1 "Always zero.";
CM_ SG_ 406 A196_FIELD3_CODE7 "Raw.";
CM_ SG_ 406 A196_B7_UNKNOWN2 "Raw.";
CM_ SG_ 406 A196_FIELD4_CODE6 "Raw.";
CM_ SG_ 128 ID80_B0 "Raw transport byte 0 of the segmented 0x80 record.";
CM_ SG_ 128 ID80_B1 "Raw transport byte 1 of the segmented 0x80 record.";
CM_ SG_ 128 ID80_B2 "Raw transport byte 2 of the segmented 0x80 record.";
CM_ SG_ 128 ID80_B3 "Raw transport byte 3 of the segmented 0x80 record.";
CM_ SG_ 128 ID80_B4 "Raw transport byte 4 of the segmented 0x80 record.";
CM_ SG_ 128 ID80_B5 "Raw transport byte 5 of the segmented 0x80 record.";
CM_ SG_ 128 ID80_B6 "Raw transport byte 6 of the segmented 0x80 record.";
CM_ SG_ 128 ID80_B7 "Raw transport byte 7 of the segmented 0x80 record.";
CM_ SG_ 133 ID85_B0 "Raw transport byte 0 of the segmented 0x85 record.";
CM_ SG_ 133 ID85_B1 "Raw transport byte 1 of the segmented 0x85 record.";
CM_ SG_ 133 ID85_B2 "Raw transport byte 2 of the segmented 0x85 record.";
CM_ SG_ 133 ID85_B3 "Raw transport byte 3 of the segmented 0x85 record.";
CM_ SG_ 133 ID85_B4 "Raw transport byte 4 of the segmented 0x85 record.";
CM_ SG_ 133 ID85_B5 "Raw transport byte 5 of the segmented 0x85 record.";
CM_ SG_ 133 ID85_B6 "Raw transport byte 6 of the segmented 0x85 record.";
CM_ SG_ 133 ID85_B7 "Raw transport byte 7 of the segmented 0x85 record.";
CM_ SG_ 129 A081_B0 "Always 0x30.";
CM_ SG_ 129 A081_B1 "Always zero.";
CM_ SG_ 129 A081_B2 "Always zero.";
CM_ SG_ 129 A081_B3 "Always zero.";
CM_ SG_ 129 A081_B4 "Always zero.";
CM_ SG_ 129 A081_B5 "Always zero.";
CM_ SG_ 129 A081_B6 "Always zero.";
CM_ SG_ 129 A081_B7 "Always zero.";
CM_ SG_ 134 A086_B0 "Always 0x30.";
CM_ SG_ 134 A086_B1 "Always zero.";
CM_ SG_ 134 A086_B2 "Always zero.";
CM_ SG_ 134 A086_B3 "Always zero.";
CM_ SG_ 134 A086_B4 "Always zero.";
CM_ SG_ 134 A086_B5 "Always zero.";
CM_ SG_ 134 A086_B6 "Always zero.";
CM_ SG_ 134 A086_B7 "Always zero.";
CM_ SG_ 256 A100_STARTUP_WORD_BE16 "0xFFFF in the first frame after power-up, zero afterwards.";
CM_ SG_ 256 A100_B2_B6_RESERVED_ZERO40 "Always zero.";
CM_ SG_ 257 A101_STARTUP_STATE8 "0x1D booting, 0x11 running (0x21 seen once, briefly).";
CM_ SG_ 257 A101_B1_B5_RESERVED_ZERO40 "Always zero.";
CM_ SG_ 258 A102_B0_RESERVED_ZERO8 "Always zero.";
CM_ SG_ 258 A102_B1_RESERVED_ZERO3 "Always zero.";
CM_ SG_ 258 A102_CONTEXT_BIT11 "Sets once per drive.";
CM_ SG_ 258 A102_B1_RESERVED4_5_ZERO2 "Always zero.";
CM_ SG_ 258 A102_CONTEXT_BIT14 "Event / context bit with several transitions per drive.";
CM_ SG_ 258 A102_B1_RESERVED7_ZERO1 "Always zero.";
CM_ SG_ 258 A102_B2_RESERVED_ZERO5 "Always zero.";
CM_ SG_ 258 A102_CONTEXT_BIT21 "Context bit, set only during part of some drives.";
CM_ SG_ 258 A102_B2_RESERVED6_7_ZERO2 "Always zero.";
CM_ SG_ 259 A103_B0_RESERVED_ZERO8 "Always zero.";
CM_ SG_ 259 A103_B1_RESERVED_ZERO8 "Always zero.";
CM_ SG_ 1282 A502_B0_CONST8 "Constant 0x19.";
CM_ SG_ 1282 A502_SLOW_CODE0_B1 "Slowly drifting code (0x69-0x92 seen), mostly +/-1 steps.";
CM_ SG_ 1282 A502_SLOW_CODE1_BE16 "Slowly drifting code (4308-4408 seen), big-endian.";
CM_ SG_ 1282 A502_TAIL_CONST_BE32 "Unit-specific constant (redacted here).";
CM_ SG_ 528 A210_RSA_SPEED_SIGN_PRESENT1 "Speed sign present (copy of Toyota RSA1.TSGN1 == 36).";
CM_ SG_ 528 A210_B0_RESERVED1_7 "Always zero.";
CM_ SG_ 528 A210_RSA_SPEED_LIMIT_VALUE8 "Speed-limit value (copy of Toyota RSA1.SPDVAL1; unit from RSA2.SPDUNT).";
CM_ SG_ 528 A210_B2 "Raw.";
CM_ SG_ 528 A210_B3 "Raw.";
CM_ SG_ 528 A210_B4 "Raw.";
CM_ SG_ 528 A210_B5_RESERVED0_5 "Always zero.";
CM_ SG_ 528 A210_RSA_MASTER_SWITCH1 "Road-sign-assist switch (copy of Toyota RSA3.TSRMSW).";
CM_ SG_ 528 A210_B5_STATUS_BIT7 "Startup / status bit.";
CM_ SG_ 528 A210_B6 "Raw.";
CM_ SG_ 514 A202_COUNTER4 "Counter mod 16, +1 per frame.";
CM_ SG_ 400 A190_TIMESTAMP_US "Radar cycle timestamp, microseconds (big-endian).";
CM_ SG_ 400 A190_COUNTER_RESERVED0 "Always zero.";
CM_ SG_ 400 A190_COUNTER4 "Cycle counter mod 16, +3 per cycle; use it to detect dropped cycles.";
CM_ SG_ 407 A197_STARTUP_PHASE1 "0 while the radar starts up, 1 once running (stays 1).";
CM_ SG_ 407 A197_B1_RESERVED1_7 "Always zero.";
CM_ SG_ 400 A190_STATUS_0_4 "Byte 0 low nibble: summary count << 2 | 2 (values 2, 6, 10).";
CM_ SG_ 400 A190_ACTIVE_SUMMARIES "Number of target summaries in this cycle (0-2): 0x191/0x192 fill first, then 0x193/0x194.";
CM_ SG_ 576 A240_B0_UNKNOWN5 "0 with the default body, 8 with a changing body.";
CM_ SG_ 576 A240_ROLLING_PHASE3 "Rolling phase 1-7 (0 at startup).";
CM_ SG_ 576 A240_RAW_WORD0_BE24 "Raw 24-bit big-endian view of three payload bytes.";
CM_ SG_ 576 A240_RAW_WORD1_BE24 "Raw 24-bit big-endian view of three payload bytes.";
CM_ SG_ 576 A240_B7_UNKNOWN8 "Raw.";
CM_ SG_ 577 A241_B0_RESERVED_ZERO5 "Always zero.";
CM_ SG_ 577 A241_ROLLING_PHASE3 "Rolling phase 1-7 (0 at startup).";
CM_ SG_ 577 A241_RAW_WORD0_BE24 "Raw 24-bit big-endian view of three payload bytes.";
CM_ SG_ 577 A241_RAW_WORD1_BE24 "Raw 24-bit big-endian view of three payload bytes.";
CM_ SG_ 577 A241_B7_RESERVED_ZERO8 "Always zero.";
CM_ SG_ 580 A244_B0_RESERVED_ZERO5 "Always zero.";
CM_ SG_ 580 A244_ROLLING_PHASE3 "Rolling phase 1-7 (0 at startup).";
CM_ SG_ 580 A244_RAW_WORD0_BE24 "Raw 24-bit big-endian view of three payload bytes.";
CM_ SG_ 580 A244_RAW_WORD1_BE24 "Raw 24-bit big-endian view of three payload bytes.";
CM_ SG_ 580 A244_B7_UNKNOWN8 "Raw.";
CM_ SG_ 581 A245_B0_RESERVED_ZERO5 "Always zero.";
CM_ SG_ 581 A245_ROLLING_PHASE3 "Rolling phase 1-7 (0 at startup).";
CM_ SG_ 581 A245_RAW_WORD0_BE24 "Raw 24-bit big-endian view of three payload bytes.";
CM_ SG_ 581 A245_RAW_WORD1_BE24 "Raw 24-bit big-endian view of three payload bytes.";
CM_ SG_ 581 A245_B7_RESERVED_ZERO8 "Always zero.";
CM_ SG_ 584 A248_B0_UNKNOWN2 "Raw.";
CM_ SG_ 584 A248_STARTUP_STATUS2 "Startup / status: 0 or 3.";
CM_ SG_ 584 A248_MUX_PHASE_RESERVED0 "Always zero.";
CM_ SG_ 584 A248_ROLLING_PHASE3 "Rolling phase 1-7 (0 at startup).";
CM_ SG_ 584 A248_B1_RESERVED_ZERO8 "Always zero.";
CM_ SG_ 584 A248_B2_STATE_BIT0 "State bit (startup transition on most drives).";
CM_ SG_ 584 A248_B2_UNKNOWN1_7 "Raw.";
CM_ SG_ 584 A248_B3_B5_RESERVED_ZERO24 "Always zero.";
CM_ SG_ 584 A248_B6_UNKNOWN_BIT0 "Raw.";
CM_ SG_ 584 A248_EVENT_PULSE1 "Rare one-frame event pulse.";
CM_ SG_ 584 A248_B6_RESERVED2_6 "Always zero.";
CM_ SG_ 584 A248_B7_RESERVED_ZERO8 "Always zero.";
CM_ SG_ 1281 A501_STATUS_40_4 "State nibble.";
CM_ SG_ 1664 A680_SELECTOR "0 / 1 mostly stationary objects, 3 mostly same-direction vehicles.";
CM_ SG_ 1664 A680_LONG_DIST "Longitudinal distance; stationary objects close at ego speed with 32 codes per metre.";
CM_ SG_ 1664 A680_LAT_DIST "Lateral position, left positive, 0.015 m per code (the object list's lateral unit).";
CM_ SG_ 1664 A680_SPEED_OVER_GROUND "Speed over ground, nominal unit; 0 for stationary objects.";
CM_ SG_ 1664 A680_FLAGS "Motion flags: bit 0 stationary, bit 1 oncoming, bit 3 seen moving; bits 2, 4, 5 raw. 1 = stationary object, 8 = moving vehicle, 9 = stopped vehicle.";
CM_ SG_ 1664 A680_STATIONARY "Flag bit 0: set on 99 % of objects slower than 0.5 m/s over ground and on 1 % of moving ones.";
CM_ SG_ 1664 A680_ONCOMING "Flag bit 1: set on 98 % of objects faster than 3 m/s toward ego and on 1 % of the others.";
CM_ SG_ 1664 A680_SEEN_MOVING "Flag bit 3: set on 86 % of same-direction moving objects and 10 % of stationary ones (with bit 0: a stopped vehicle).";
CM_ SG_ 1664 A680_LAT_SPEED_CODE "Lateral speed over ground, left positive, about 0.13-0.18 m/s per code (0.15 nominal); 0 on stationary objects.";
CM_ SG_ 1664 A680_B7_HIGH4 "14 on most frames.";
CM_ SG_ 1664 A680_B7_LOW4 "0xA with selector 0, 0xF with selector 1 / 3.";
CM_ SG_ 401 A191_B0_RESERVED0 "Always zero.";
CM_ SG_ 401 A191_PAIR_SCORE_CODE7 "Target score: 91-100 while active, 127 in the sentinel.";
CM_ SG_ 401 A191_B1_RESERVED0 "Always zero.";
CM_ SG_ 401 A191_PAIR_TRACK_AGE7 "Target age in radar cycles, saturates at 126; 127 in the sentinel.";
CM_ SG_ 401 A191_B3_RESERVED0_2 "Always zero.";
CM_ SG_ 401 A191_PAIR_TRACK_ID6 "Target track code; a code can move between the A (0x191) and B (0x193) pairs.";
CM_ SG_ 401 A191_B4_RESERVED0_2 "Always zero.";
CM_ SG_ 401 A191_PAIR_DESCRIPTOR0_CODE6 "Class template width, m: 1.8 car, 2.2 truck (the class on 0x239 when this is the ACC target); rare other values 2.5-3.0.";
CM_ SG_ 401 A191_B5_RESERVED0_3 "Zero in practice (seen as 4 once, one frame before a sentinel).";
CM_ SG_ 401 A191_PAIR_FIELD5_CODE5 "Counter that grows with target age and saturates at 30 (31 in the sentinel).";
CM_ SG_ 401 A191_B6_RESERVED0 "Always zero.";
CM_ SG_ 401 A191_PAIR_DESCRIPTOR1_CODE7 "Class template height-like size, m: 1.5 car, 2.3 truck.";
CM_ SG_ 401 A191_PAIR_DESCRIPTOR2_CODE8 "Class template length, m: 4.5 car, 12.0 truck; rare other values from 2.0.";
CM_ SG_ 402 A192_WORD0_RESERVED_ZERO3 "Always zero.";
CM_ SG_ 402 A192_PAIR_RANGE_CODE13 "Distance of one internal-tracker target: (code - 160) / 16 m, the object list encoding.";
CM_ SG_ 402 A192_WORD1_RESERVED_ZERO3 "Always zero.";
CM_ SG_ 402 A192_PAIR_FIELD1_CODE13 "Lateral position of the same target: (code - 2048) * 0.015 m, left positive; keep all 13 bits.";
CM_ SG_ 403 A193_B0_RESERVED0 "Always zero.";
CM_ SG_ 403 A193_PAIR_SCORE_CODE7 "Target score: 91-100 while active, 127 in the sentinel.";
CM_ SG_ 403 A193_B1_RESERVED0 "Always zero.";
CM_ SG_ 403 A193_PAIR_TRACK_AGE7 "Target age in radar cycles, saturates at 126; 127 in the sentinel.";
CM_ SG_ 403 A193_B3_RESERVED0_2 "Always zero.";
CM_ SG_ 403 A193_PAIR_TRACK_ID6 "Target track code; a code can move between the A (0x191) and B (0x193) pairs.";
CM_ SG_ 403 A193_B4_RESERVED0_2 "Always zero.";
CM_ SG_ 403 A193_PAIR_DESCRIPTOR0_CODE6 "Class template width, m: 1.8 car, 2.2 truck.";
CM_ SG_ 403 A193_B5_RESERVED0_3 "Zero; 7 in the sentinel.";
CM_ SG_ 403 A193_PAIR_FIELD5_CODE5 "Counter that grows with target age and saturates at 30 (31 in the sentinel).";
CM_ SG_ 403 A193_B6_RESERVED0 "Always zero.";
CM_ SG_ 403 A193_PAIR_DESCRIPTOR1_CODE7 "Class template height-like size, m: 1.5 car, 2.3 truck.";
CM_ SG_ 403 A193_PAIR_DESCRIPTOR2_CODE8 "Class template length, m: 4.5 car, 12.0 truck.";
CM_ SG_ 404 A194_WORD0_RESERVED_ZERO3 "Always zero.";
CM_ SG_ 404 A194_PAIR_RANGE_CODE13 "Distance of one internal-tracker target: (code - 160) / 16 m, the object list encoding.";
CM_ SG_ 404 A194_WORD1_RESERVED_ZERO3 "Always zero.";
CM_ SG_ 404 A194_PAIR_FIELD1_CODE13 "Lateral position of the same target: (code - 2048) * 0.015 m, left positive; keep all 13 bits.";
CM_ SG_ 565 A235_B0_CHECK_BYTE "Check byte over the rest of the frame.";
CM_ SG_ 565 A235_STATUS_MUX4 "Byte-1 low nibble: 5 with an ACC target, 1 without (idle payload), 15 at start-up.";
CM_ SG_ 565 A235_COUNTER4 "Rolling counter.";
CM_ SG_ 567 A237_B0_CHECK_BYTE "Check byte: an affine parity function of bytes 1-7.";
CM_ SG_ 567 A237_STATUS_MUX4 "Byte-1 low nibble: the top four bits of A237_ACC_TARGET_DISTANCE_CODE.";
CM_ SG_ 567 A237_COUNTER4 "Rolling counter.";
CM_ SG_ 569 A239_B0_CHECK_BYTE "Check byte: an affine parity function of bytes 1-7.";
CM_ SG_ 569 A239_STATUS_MUX4 "ACC target class: 1 car, 2 truck (the 0x191 template class), 0 / 4 / 5 / 6 other, 7 no target.";
CM_ SG_ 569 A239_TARGET_IN_OBJECT_LIST "1 while the ACC target also has an object in the 0x80 list.";
CM_ SG_ 569 A239_TARGET_PRESENT "1 with an ACC target.";
CM_ SG_ 569 A239_TIMESTAMP_US "Radar cycle timestamp of this target update, microseconds, on the 0x190 clock: equal to A190_TIMESTAMP_US in 73 % of frames, within one cycle in 99.8 %.";
CM_ SG_ 569 A239_COUNTER4 "Rolling counter.";
CM_ SG_ 571 A23B_B0_CHECK_BYTE "Check byte: CRC8 (poly 0x1D, init 0, MSB first) over B1, B2, XOR 0x59, then XOR 0x3B / 0x76 / 0xEC / 0xC5 for set bits 4 / 5 / 6 / 7 of B1. Startup frames 00 0F FF differ.";
CM_ SG_ 571 A23B_STATUS_MUX4 "Byte-1 low nibble: high bits of the target width (1 for widths of 256 cm and more).";
CM_ SG_ 571 A23B_TARGET_WIDTH_CM "Width of the ACC target, cm: 0 without a target, 140-220 for the car class (median 171), 200-280 for the truck class.";
CM_ SG_ 571 A23B_COUNTER4 "Rolling counter.";
VAL_ 257 A101_STARTUP_STATE8 29 "startup_0x1D" 17 "post_startup_base_0x11" 33 "transient_0x21" ;
VAL_ 258 A102_CONTEXT_BIT11 0 "STATE_0x0" 1 "STATE_0x1" ;
VAL_ 258 A102_CONTEXT_BIT14 0 "STATE_0x0" 1 "STATE_0x1" ;
VAL_ 258 A102_CONTEXT_BIT21 0 "STATE_0x0" 1 "STATE_0x1" ;
VAL_ 400 A190_STATUS_0_4 0 "STATE_0x0" 1 "STATE_0x1" 2 "STATE_0x2" 3 "STATE_0x3" 4 "STATE_0x4" 5 "STATE_0x5" 6 "STATE_0x6" 7 "STATE_0x7" 8 "STATE_0x8" 9 "STATE_0x9" 10 "STATE_0xA" 11 "STATE_0xB" 12 "STATE_0xC" 13 "STATE_0xD" 14 "STATE_0xE" 15 "STATE_0xF" ;
VAL_ 400 A190_COUNTER4 0 "COUNT_0x0" 1 "COUNT_0x1" 2 "COUNT_0x2" 3 "COUNT_0x3" 4 "COUNT_0x4" 5 "COUNT_0x5" 6 "COUNT_0x6" 7 "COUNT_0x7" 8 "COUNT_0x8" 9 "COUNT_0x9" 10 "COUNT_0xA" 11 "COUNT_0xB" 12 "COUNT_0xC" 13 "COUNT_0xD" 14 "COUNT_0xE" 15 "COUNT_0xF" ;
VAL_ 407 A197_STARTUP_PHASE1 0 "STATE_0x0" 1 "STATE_0x1" ;
VAL_ 514 A202_COUNTER4 0 "COUNT_0x0" 1 "COUNT_0x1" 2 "COUNT_0x2" 3 "COUNT_0x3" 4 "COUNT_0x4" 5 "COUNT_0x5" 6 "COUNT_0x6" 7 "COUNT_0x7" 8 "COUNT_0x8" 9 "COUNT_0x9" 10 "COUNT_0xA" 11 "COUNT_0xB" 12 "COUNT_0xC" 13 "COUNT_0xD" 14 "COUNT_0xE" 15 "COUNT_0xF" ;
VAL_ 528 A210_RSA_SPEED_SIGN_PRESENT1 0 "STATE_0x0" 1 "STATE_0x1" ;
VAL_ 528 A210_RSA_MASTER_SWITCH1 0 "STATE_0x0" 1 "STATE_0x1" ;
VAL_ 528 A210_B5_STATUS_BIT7 0 "STATE_0x0" 1 "STATE_0x1" ;
VAL_ 576 A240_ROLLING_PHASE3 0 "STATE_0x0" 1 "STATE_0x1" 2 "STATE_0x2" 3 "STATE_0x3" 4 "STATE_0x4" 5 "STATE_0x5" 6 "STATE_0x6" 7 "STATE_0x7" ;
VAL_ 577 A241_ROLLING_PHASE3 0 "STATE_0x0" 1 "STATE_0x1" 2 "STATE_0x2" 3 "STATE_0x3" 4 "STATE_0x4" 5 "STATE_0x5" 6 "STATE_0x6" 7 "STATE_0x7" ;
VAL_ 580 A244_ROLLING_PHASE3 0 "STATE_0x0" 1 "STATE_0x1" 2 "STATE_0x2" 3 "STATE_0x3" 4 "STATE_0x4" 5 "STATE_0x5" 6 "STATE_0x6" 7 "STATE_0x7" ;
VAL_ 581 A245_ROLLING_PHASE3 0 "STATE_0x0" 1 "STATE_0x1" 2 "STATE_0x2" 3 "STATE_0x3" 4 "STATE_0x4" 5 "STATE_0x5" 6 "STATE_0x6" 7 "STATE_0x7" ;
VAL_ 584 A248_STARTUP_STATUS2 0 "STATE_0x0" 1 "STATE_0x1" 2 "STATE_0x2" 3 "STATE_0x3" ;
VAL_ 584 A248_ROLLING_PHASE3 0 "STATE_0x0" 1 "STATE_0x1" 2 "STATE_0x2" 3 "STATE_0x3" 4 "STATE_0x4" 5 "STATE_0x5" 6 "STATE_0x6" 7 "STATE_0x7" ;
VAL_ 584 A248_B2_STATE_BIT0 0 "STATE_0x0" 1 "STATE_0x1" ;
VAL_ 584 A248_EVENT_PULSE1 0 "STATE_0x0" 1 "STATE_0x1" ;
VAL_ 591 A24F_STARTUP_PHASE1 0 "STATE_0x0" 1 "STATE_0x1" ;
VAL_ 1281 A501_STATUS_40_4 0 "STATE_0x0" 1 "STATE_0x1" 2 "STATE_0x2" 3 "STATE_0x3" 4 "STATE_0x4" 5 "STATE_0x5" 6 "STATE_0x6" 7 "STATE_0x7" 8 "STATE_0x8" 9 "STATE_0x9" 10 "STATE_0xA" 11 "STATE_0xB" 12 "STATE_0xC" 13 "STATE_0xD" 14 "STATE_0xE" 15 "STATE_0xF" ;
VAL_ 565 A235_STATUS_MUX4 0 "STATE_0x0" 1 "STATE_0x1" 2 "STATE_0x2" 3 "STATE_0x3" 4 "STATE_0x4" 5 "STATE_0x5" 6 "STATE_0x6" 7 "STATE_0x7" 8 "STATE_0x8" 9 "STATE_0x9" 10 "STATE_0xA" 11 "STATE_0xB" 12 "STATE_0xC" 13 "STATE_0xD" 14 "STATE_0xE" 15 "STATE_0xF" ;
VAL_ 565 A235_COUNTER4 0 "COUNT_0x0" 1 "COUNT_0x1" 2 "COUNT_0x2" 3 "COUNT_0x3" 4 "COUNT_0x4" 5 "COUNT_0x5" 6 "COUNT_0x6" 7 "COUNT_0x7" 8 "COUNT_0x8" 9 "COUNT_0x9" 10 "COUNT_0xA" 11 "COUNT_0xB" 12 "COUNT_0xC" 13 "COUNT_0xD" 14 "COUNT_0xE" 15 "COUNT_0xF" ;
VAL_ 567 A237_STATUS_MUX4 0 "STATE_0x0" 1 "STATE_0x1" 2 "STATE_0x2" 3 "STATE_0x3" 4 "STATE_0x4" 5 "STATE_0x5" 6 "STATE_0x6" 7 "STATE_0x7" 8 "STATE_0x8" 9 "STATE_0x9" 10 "STATE_0xA" 11 "STATE_0xB" 12 "STATE_0xC" 13 "STATE_0xD" 14 "STATE_0xE" 15 "STATE_0xF" ;
VAL_ 567 A237_COUNTER4 0 "COUNT_0x0" 1 "COUNT_0x1" 2 "COUNT_0x2" 3 "COUNT_0x3" 4 "COUNT_0x4" 5 "COUNT_0x5" 6 "COUNT_0x6" 7 "COUNT_0x7" 8 "COUNT_0x8" 9 "COUNT_0x9" 10 "COUNT_0xA" 11 "COUNT_0xB" 12 "COUNT_0xC" 13 "COUNT_0xD" 14 "COUNT_0xE" 15 "COUNT_0xF" ;
VAL_ 569 A239_STATUS_MUX4 0 "OTHER_0" 1 "CAR" 2 "TRUCK" 4 "OTHER_4" 5 "OTHER_5" 6 "OTHER_6" 7 "NO_TARGET" 15 "STARTUP" ;
VAL_ 569 A239_COUNTER4 0 "COUNT_0x0" 1 "COUNT_0x1" 2 "COUNT_0x2" 3 "COUNT_0x3" 4 "COUNT_0x4" 5 "COUNT_0x5" 6 "COUNT_0x6" 7 "COUNT_0x7" 8 "COUNT_0x8" 9 "COUNT_0x9" 10 "COUNT_0xA" 11 "COUNT_0xB" 12 "COUNT_0xC" 13 "COUNT_0xD" 14 "COUNT_0xE" 15 "COUNT_0xF" ;
VAL_ 571 A23B_STATUS_MUX4 0 "STATE_0x0" 1 "STATE_0x1" 2 "STATE_0x2" 3 "STATE_0x3" 4 "STATE_0x4" 5 "STATE_0x5" 6 "STATE_0x6" 7 "STATE_0x7" 8 "STATE_0x8" 9 "STATE_0x9" 10 "STATE_0xA" 11 "STATE_0xB" 12 "STATE_0xC" 13 "STATE_0xD" 14 "STATE_0xE" 15 "STATE_0xF" ;
VAL_ 571 A23B_COUNTER4 0 "COUNT_0x0" 1 "COUNT_0x1" 2 "COUNT_0x2" 3 "COUNT_0x3" 4 "COUNT_0x4" 5 "COUNT_0x5" 6 "COUNT_0x6" 7 "COUNT_0x7" 8 "COUNT_0x8" 9 "COUNT_0x9" 10 "COUNT_0xA" 11 "COUNT_0xB" 12 "COUNT_0xC" 13 "COUNT_0xD" 14 "COUNT_0xE" 15 "COUNT_0xF" ;
